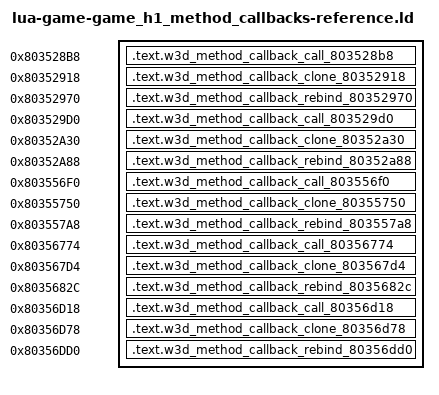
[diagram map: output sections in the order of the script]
/* Generated reference-only placements. All bodies are source-built. */
OUTPUT_FORMAT("elf32-powerpc")
OUTPUT_ARCH(powerpc)
ENTRY(w3d_method_callback_call_803528b8)
_SDA_BASE_ = 0x804b2540;
_SDA2_BASE_ = 0x804c2540;
w3d_heap_allocate_entry_a = 0x801fe1d8;
w3d_method_callback_vtable_80413980 = 0x80413980;
w3d_method_callback_vtable_804139a0 = 0x804139a0;
w3d_method_callback_vtable_80413c88 = 0x80413c88;
w3d_method_callback_vtable_804170d8 = 0x804170d8;
w3d_method_callback_vtable_80417130 = 0x80417130;
SECTIONS {
  .text.w3d_method_callback_call_803528b8 0x803528b8 : { *(.text.w3d_method_callback_call_803528b8) }
  .text.w3d_method_callback_clone_80352918 0x80352918 : { *(.text.w3d_method_callback_clone_80352918) }
  .text.w3d_method_callback_rebind_80352970 0x80352970 : { *(.text.w3d_method_callback_rebind_80352970) }
  .text.w3d_method_callback_call_803529d0 0x803529d0 : { *(.text.w3d_method_callback_call_803529d0) }
  .text.w3d_method_callback_clone_80352a30 0x80352a30 : { *(.text.w3d_method_callback_clone_80352a30) }
  .text.w3d_method_callback_rebind_80352a88 0x80352a88 : { *(.text.w3d_method_callback_rebind_80352a88) }
  .text.w3d_method_callback_call_803556f0 0x803556f0 : { *(.text.w3d_method_callback_call_803556f0) }
  .text.w3d_method_callback_clone_80355750 0x80355750 : { *(.text.w3d_method_callback_clone_80355750) }
  .text.w3d_method_callback_rebind_803557a8 0x803557a8 : { *(.text.w3d_method_callback_rebind_803557a8) }
  .text.w3d_method_callback_call_80356774 0x80356774 : { *(.text.w3d_method_callback_call_80356774) }
  .text.w3d_method_callback_clone_803567d4 0x803567d4 : { *(.text.w3d_method_callback_clone_803567d4) }
  .text.w3d_method_callback_rebind_8035682c 0x8035682c : { *(.text.w3d_method_callback_rebind_8035682c) }
  .text.w3d_method_callback_call_80356d18 0x80356d18 : { *(.text.w3d_method_callback_call_80356d18) }
  .text.w3d_method_callback_clone_80356d78 0x80356d78 : { *(.text.w3d_method_callback_clone_80356d78) }
  .text.w3d_method_callback_rebind_80356dd0 0x80356dd0 : { *(.text.w3d_method_callback_rebind_80356dd0) }
  /DISCARD/ : { *(.text*) *(.rodata*) *(.data*) *(.bss*) *(.sdata*) *(.sbss*) *(.comment) }
}
